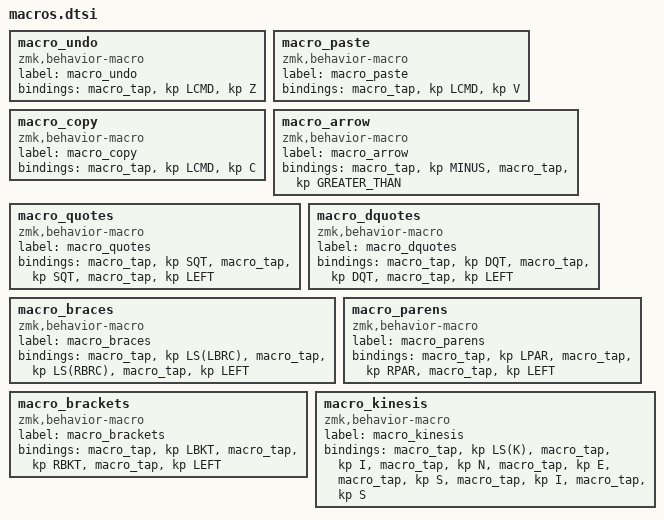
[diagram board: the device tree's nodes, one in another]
    macro_undo: macro_undo{
        compatible = "zmk,behavior-macro";
        label = "macro_undo";
        #binding-cells = <0>;
        bindings = <&macro_tap &kp LCMD &kp Z>;
    };

    macro_paste: macro_paste{
        compatible = "zmk,behavior-macro";
        label = "macro_paste";
        #binding-cells = <0>;
        bindings = <&macro_tap &kp LCMD &kp V>;
    };

    macro_copy: macro_copy{
        compatible = "zmk,behavior-macro";
        label = "macro_copy";
        #binding-cells = <0>;
        bindings = <&macro_tap &kp LCMD &kp C>;
    };

    // Text Snippet & Helper Macros
    macro_arrow: macro_arrow{
        compatible = "zmk,behavior-macro";
        label = "macro_arrow";
        #binding-cells = <0>;
        bindings = <&macro_tap &kp MINUS>, <&macro_tap &kp GREATER_THAN>;
    };

    macro_quotes: macro_quotes{
        compatible = "zmk,behavior-macro";
        label = "macro_quotes";
        #binding-cells = <0>;
        bindings = <&macro_tap &kp SQT>, <&macro_tap &kp SQT>, <&macro_tap &kp LEFT>;
    };

    macro_dquotes: macro_dquotes{
        compatible = "zmk,behavior-macro";
        label = "macro_dquotes";
        #binding-cells = <0>;
        bindings = <&macro_tap &kp DQT>, <&macro_tap &kp DQT>, <&macro_tap &kp LEFT>;
    };

    macro_braces: macro_braces{
        compatible = "zmk,behavior-macro";
        label = "macro_braces";
        #binding-cells = <0>;
        bindings = <&macro_tap &kp LS(LBRC)>, <&macro_tap &kp LS(RBRC)>, <&macro_tap &kp LEFT>;
    };

    macro_parens: macro_parens{
        compatible = "zmk,behavior-macro";
        label = "macro_parens";
        #binding-cells = <0>;
        bindings = <&macro_tap &kp LPAR>, <&macro_tap &kp RPAR>, <&macro_tap &kp LEFT>;
    };

    macro_brackets: macro_brackets{
        compatible = "zmk,behavior-macro";
        label = "macro_brackets";
        #binding-cells = <0>;
        bindings = <&macro_tap &kp LBKT>, <&macro_tap &kp RBKT>, <&macro_tap &kp LEFT>;
    };

    macro_kinesis: macro_kinesis{
        compatible = "zmk,behavior-macro";
        label = "macro_kinesis";
        #binding-cells = <0>;
        bindings = <&macro_tap &kp LS(K)>, <&macro_tap &kp I>, <&macro_tap &kp N>, <&macro_tap &kp E>, <&macro_tap &kp S>, <&macro_tap &kp I>, <&macro_tap &kp S>;
    };
